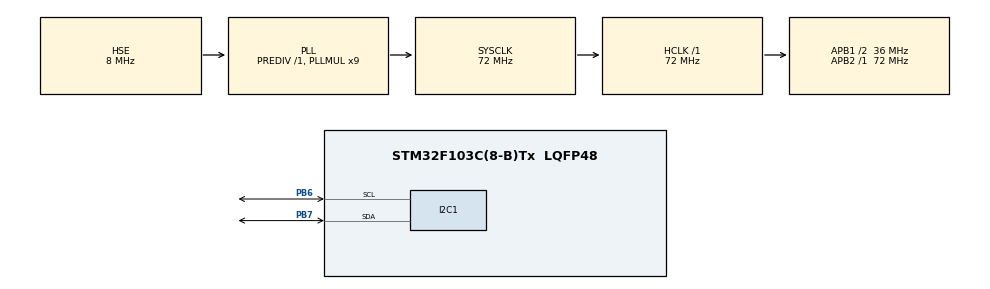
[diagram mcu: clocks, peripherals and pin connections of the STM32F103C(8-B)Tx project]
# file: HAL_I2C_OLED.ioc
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I2C1.I2C_Mode=I2C_Fast
Mcu.Family=STM32F1
Mcu.Name=STM32F103C(8-B)Tx
Mcu.Package=LQFP48
NVIC.PriorityGroup=NVIC_PRIORITYGROUP_4
PA13.Mode=Serial_Wire
PA13.Signal=SYS_JTMS-SWDIO
PA14.Mode=Serial_Wire
PA14.Signal=SYS_JTCK-SWCLK
PB6.Mode=I2C
PB6.Signal=I2C1_SCL
PB7.Mode=I2C
PB7.Signal=I2C1_SDA
PD0-OSC_IN.Mode=HSE-External-Oscillator
PD0-OSC_IN.Signal=RCC_OSC_IN
PD1-OSC_OUT.Mode=HSE-External-Oscillator
PD1-OSC_OUT.Signal=RCC_OSC_OUT
ProjectManager.HeapSize=0x200
ProjectManager.StackSize=0x400
ProjectManager.TargetToolchain=MDK-ARM V5.32
RCC.AHBFreq_Value=72000000
RCC.APB1CLKDivider=RCC_HCLK_DIV2
RCC.APB1Freq_Value=36000000
RCC.APB1TimFreq_Value=72000000
RCC.APB2Freq_Value=72000000
RCC.APB2TimFreq_Value=72000000
RCC.HCLKFreq_Value=72000000
RCC.PLLMUL=RCC_PLL_MUL9
RCC.PLLSourceVirtual=RCC_PLLSOURCE_HSE
RCC.SYSCLKFreq_VALUE=72000000
RCC.SYSCLKSource=RCC_SYSCLKSOURCE_PLLCLK
RCC.USBFreq_Value=72000000
board=custom

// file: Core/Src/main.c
/* USER CODE BEGIN Header */
/**
  ******************************************************************************
  * @file           : main.c
  * @brief          : Main program body
  ******************************************************************************
  * @attention
  *
  * Copyright (c) 2022 STMicroelectronics.
  * All rights reserved.
  *
  * This software is licensed under terms that can be found in the LICENSE file
  * in the root directory of this software component.
  * If no LICENSE file comes with this software, it is provided AS-IS.
  *
  ******************************************************************************
  */
/* USER CODE END Header */
#include "main.h"
#include "i2c.h"
#include "gpio.h"

/* USER CODE BEGIN Includes */
#define command 0x00
#define data 0x40
#define qijian 0x78

uint8_t suzu[] = {/*--  文字:  蒙  --*/
/*--  幼圆12;  此字体下对应的点阵为：宽x高=16x16   --*/
0x04,0xFC,0xFC,0xFC,0xFE,0xFE,0xFC,0xFC,0xFC,0xFC,0xFE,0xFE,0xFC,0xFC,0x74,0x00,
0x04,0xD4,0xD5,0x5F,0x7F,0xEF,0xBF,0xFF,0xFD,0x7D,0x1F,0x37,0x63,0x63,0xC0,0x00,
};

uint8_t suzu_command_data[] = {0xAE, 0x40, 0xb0, 0xc8, 0x81, 0xff, 0xa1, 0xa6,
0xa8, 0x1f, 0xd3, 0x00, 0xd5, 0xf0, 0xd9, 0x22, 0xda, 0x02, 0xd8, 0x49,
0x8d, 0x14, 0xaf};

uint8_t suzu_command_data2[] = {0X8D, 0x14, 0xaf};

void  OLED_Init()
{
	HAL_Delay(1);
	HAL_I2C_Mem_Write(&hi2c1, qijian, command , 8, suzu_command_data, sizeof(suzu_command_data), 5000);
}

void OLED_Display_On(void)
{
	HAL_I2C_Mem_Write(&hi2c1, qijian, command , 8, suzu_command_data2, sizeof(suzu_command_data2), 500);
}

void OLED_Set_Pos(unsigned char x, unsigned char y)
{
	uint8_t neibu[] = {0xb0+y, ((x&0xf0)>>4)|0x10, (x&0x0f)};
	HAL_I2C_Mem_Write(&hi2c1, qijian, command , 8, neibu, sizeof (neibu), 500);
}

void OLED_ShowCHinese(uint8_t x,uint8_t y,uint8_t no,uint8_t font_width,uint8_t font_height)
{
	uint8_t t, i;
        for(i=0;i<(font_height/8);i++)				/*font_height朿大忼为32，这张屏只有8个页（行），每页4个位*/
	 {
			OLED_Set_Pos(x,y+i);
			for(t=0;t<font_width;t++)		/*font_width朿大忼为128，屏幕只有这么大*/
			{
				HAL_I2C_Mem_Write(&hi2c1, qijian, data, 8, suzu, sizeof(suzu), 500);
			}
	 }
}

void OLED_Clear(void){
	uint8_t i,n;
	uint8_t neibu[] = {0x00, 0x10};
	 for(i=0;i<8;i++)
	 {
			HAL_I2C_Mem_Write(&hi2c1, qijian, command , 8, (uint8_t *)(0xb0+i), sizeof (0xb0), 500);
			HAL_I2C_Mem_Write(&hi2c1, qijian, command , 8, neibu, sizeof (neibu), 500);
			for(n=0;n<128;n++)
		 HAL_I2C_Mem_Write(&hi2c1, qijian, data, 8, 0, sizeof(0), 5);
	 } 														//更新显示
}
/* USER CODE END Includes */

void SystemClock_Config(void);

int main(void)
{

  /* MCU Configuration--------------------------------------------------------*/

  /* Reset of all peripherals, Initializes the Flash interface and the Systick. */
  HAL_Init();

  /* Configure the system clock */
  SystemClock_Config();

  /* Initialize all configured peripherals */
  MX_GPIO_Init();
  MX_I2C1_Init();
  /* USER CODE BEGIN 2 */
	OLED_Clear();
	OLED_Init();
	OLED_Display_On();
	OLED_ShowCHinese(0,0,0,16,16);
	HAL_Delay(200);
	OLED_Clear();
  /* USER CODE END 2 */

  /* Infinite loop */
  while (1)
  {

  }
}

void SystemClock_Config(void)
{
  RCC_OscInitTypeDef RCC_OscInitStruct = {0};
  RCC_ClkInitTypeDef RCC_ClkInitStruct = {0};

  /** Initializes the RCC Oscillators according to the specified parameters
  * in the RCC_OscInitTypeDef structure.
  */
  RCC_OscInitStruct.OscillatorType = RCC_OSCILLATORTYPE_HSE;
  RCC_OscInitStruct.HSEState = RCC_HSE_ON;
  RCC_OscInitStruct.HSEPredivValue = RCC_HSE_PREDIV_DIV1;
  RCC_OscInitStruct.HSIState = RCC_HSI_ON;
  RCC_OscInitStruct.PLL.PLLState = RCC_PLL_ON;
  RCC_OscInitStruct.PLL.PLLSource = RCC_PLLSOURCE_HSE;
  RCC_OscInitStruct.PLL.PLLMUL = RCC_PLL_MUL9;
  if (HAL_RCC_OscConfig(&RCC_OscInitStruct) != HAL_OK)
  {
    Error_Handler();
  }
  /** Initializes the CPU, AHB and APB buses clocks
  */
  RCC_ClkInitStruct.ClockType = RCC_CLOCKTYPE_HCLK|RCC_CLOCKTYPE_SYSCLK
                              |RCC_CLOCKTYPE_PCLK1|RCC_CLOCKTYPE_PCLK2;
  RCC_ClkInitStruct.SYSCLKSource = RCC_SYSCLKSOURCE_PLLCLK;
  RCC_ClkInitStruct.AHBCLKDivider = RCC_SYSCLK_DIV1;
  RCC_ClkInitStruct.APB1CLKDivider = RCC_HCLK_DIV2;
  RCC_ClkInitStruct.APB2CLKDivider = RCC_HCLK_DIV1;

  if (HAL_RCC_ClockConfig(&RCC_ClkInitStruct, FLASH_LATENCY_2) != HAL_OK)
  {
    Error_Handler();
  }
}

void Error_Handler(void)
{
  __disable_irq();
  while (1)
  {
  }
}
